# STM32H730 register map
File version: 1.9
CPU: CM7 r0p1, little endian, MPU, FPU, 4 interrupt priority bits
Registers are 32-bit, read-write, reset 0x0 unless marked. A register's access mark holds for its fields unless they carry their own. Offsets are from the block's base; [hi:lo] are bit positions; {n}, {i} and the like mark numbered series.

## CRC — Cryptographic processor
Base 0x58024C00
0x00 DR reset 0xFFFFFFFF — Data register
  [31:0] DR — Data Register
0x04 IDR — Independent Data register
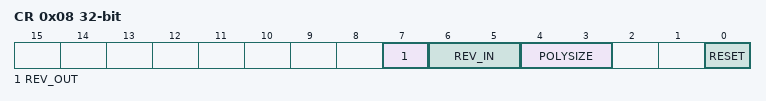
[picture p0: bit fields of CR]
0x08 CR access per field — Control register
  [7] REV_OUT rw — Reverse output data
  [6:5] REV_IN rw — Reverse input data
  [4:3] POLYSIZE rw — Polynomial size
  [0] RESET wo — RESET bit
0x10 INIT — Initial CRC value
  [31:0] CRC_INIT — Programmable initial CRC value
0x14 POL reset 0x4C11DB7 — CRC polynomial
  [31:0] POL — Programmable polynomial

## CRYP — Cryptographic processor
Base 0x48021000
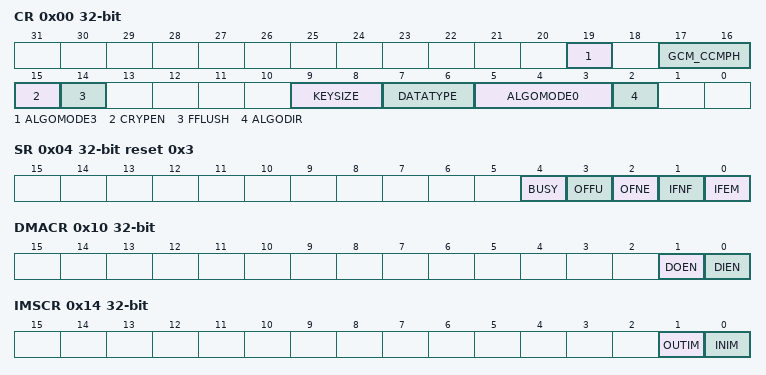
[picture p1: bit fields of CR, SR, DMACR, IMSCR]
0x00 CR access per field — control register
  [19] ALGOMODE3 rw — ALGOMODE
  [17:16] GCM_CCMPH rw
  [15] CRYPEN rw — Cryptographic processor enable
  [14] FFLUSH wo — FIFO flush
  [9:8] KEYSIZE rw — Key size selection (AES mode only)
  [7:6] DATATYPE rw — Data type selection
  [5:3] ALGOMODE0 rw — Algorithm mode
  [2] ALGODIR rw — Algorithm direction
0x04 SR ro reset 0x3 — status register
  [4] BUSY — Busy bit
  [3] OFFU — Output FIFO full
  [2] OFNE — Output FIFO not empty
  [1] IFNF — Input FIFO not full
  [0] IFEM — Input FIFO empty
0x08 DIN — data input register
  [31:0] DATAIN — Data input
0x0C DOUT ro — data output register
  [31:0] DATAOUT — Data output
0x10 DMACR — DMA control register
  [1] DOEN — DMA output enable
  [0] DIEN — DMA input enable
0x14 IMSCR — interrupt mask set/clear register
  [1] OUTIM — Output FIFO service interrupt mask
  [0] INIM — Input FIFO service interrupt mask
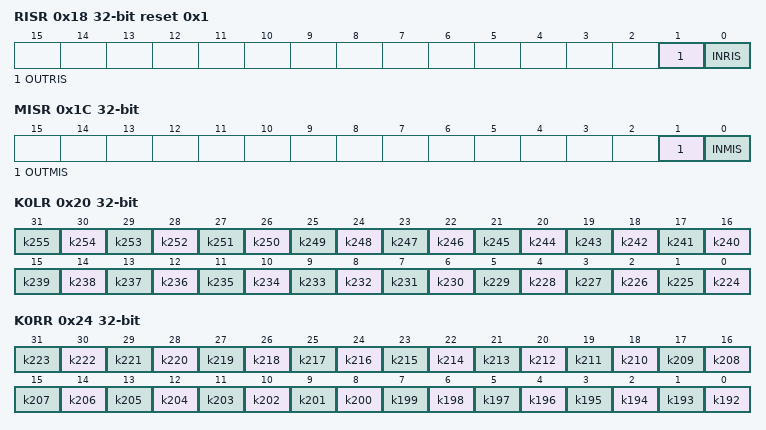
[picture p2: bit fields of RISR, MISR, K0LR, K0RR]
0x18 RISR ro reset 0x1 — raw interrupt status register
  [1] OUTRIS — Output FIFO service raw interrupt status
  [0] INRIS — Input FIFO service raw interrupt status
0x1C MISR ro — masked interrupt status register
  [1] OUTMIS — Output FIFO service masked interrupt status
  [0] INMIS — Input FIFO service masked interrupt status
0x20 K0LR wo — key registers
  [n-224] k{n} (n=224..255)
0x24 K0RR wo — key registers
  [n-192] k{n} (n=192..223)
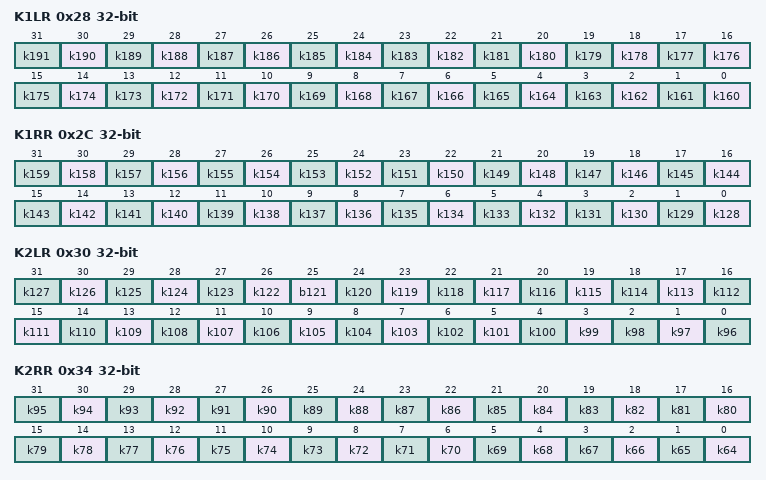
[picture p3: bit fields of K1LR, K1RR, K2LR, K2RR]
0x28 K1LR wo — key registers
  [n-160] k{n} (n=160..191)
0x2C K1RR wo — key registers
  [n-128] k{n} (n=128..159)
0x30 K2LR wo — key registers
  [n-96] k{n} (n=122..127), [25] b121, [n-96] k{n} (n=96..120)
0x34 K2RR wo — key registers
  [n-64] k{n} (n=64..95)
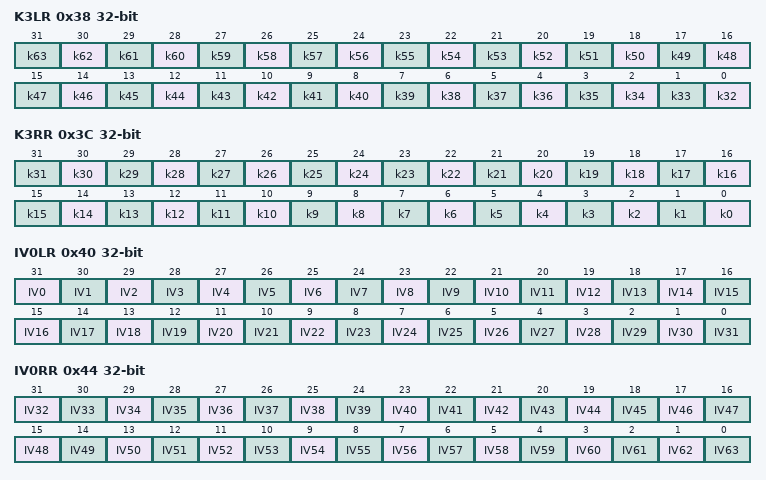
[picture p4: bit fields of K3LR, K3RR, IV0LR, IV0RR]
0x38 K3LR wo — key registers
  [n-32] k{n} (n=32..63)
0x3C K3RR wo — key registers
  [n] k{n} (n=0..31)
0x40 IV0LR — Initialization vector register 0L
  [31-n] IV{n} (n=0..31)
0x44 IV0RR — initialization vector register 0R
  [63-n] IV{n} (n=32..63)
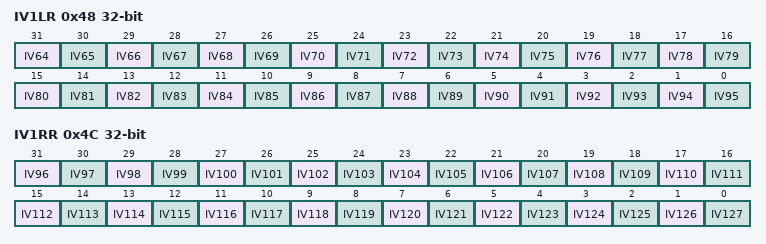
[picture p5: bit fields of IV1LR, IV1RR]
0x48 IV1LR — Initialization vector register 1L
  [95-n] IV{n} (n=64..95)
0x4C IV1RR — Initialization vector register 1R
  [127-n] IV{n} (n=96..127)
{0x50+4i} CSGCMCCM{i}R (i=0..7) — context swap register
{0x70+4i} CSGCM{i}R (i=0..7) — context swap register

## DCMI — Digital camera interface
Base 0x48020000
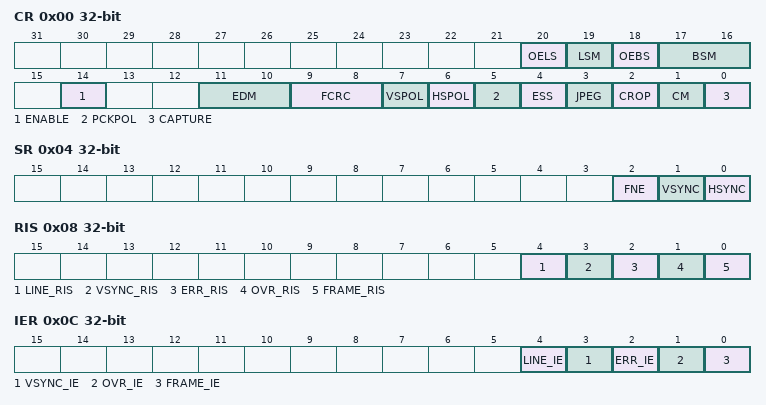
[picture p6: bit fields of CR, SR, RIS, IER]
0x00 CR — control register 1
  [20] OELS — Odd/Even Line Select (Line Select Start)
  [19] LSM — Line Select mode
  [18] OEBS — Odd/Even Byte Select (Byte Select Start)
  [17:16] BSM — Byte Select mode
  [14] ENABLE — DCMI enable
  [11:10] EDM — Extended data mode
  [9:8] FCRC — Frame capture rate control
  [7] VSPOL — Vertical synchronization polarity
  [6] HSPOL — Horizontal synchronization polarity
  [5] PCKPOL — Pixel clock polarity
  [4] ESS — Embedded synchronization select
  [3] JPEG — JPEG format
  [2] CROP — Crop feature
  [1] CM — Capture mode
  [0] CAPTURE — Capture enable
0x04 SR ro — status register
  [2] FNE — FIFO not empty
  [1] VSYNC
  [0] HSYNC
0x08 RIS ro — raw interrupt status register
  [4] LINE_RIS — Line raw interrupt status
  [3] VSYNC_RIS — VSYNC raw interrupt status
  [2] ERR_RIS — Synchronization error raw interrupt status
  [1] OVR_RIS — Overrun raw interrupt status
  [0] FRAME_RIS — Capture complete raw interrupt status
0x0C IER — interrupt enable register
  [4] LINE_IE — Line interrupt enable
  [3] VSYNC_IE — VSYNC interrupt enable
  [2] ERR_IE — Synchronization error interrupt enable
  [1] OVR_IE — Overrun interrupt enable
  [0] FRAME_IE — Capture complete interrupt enable
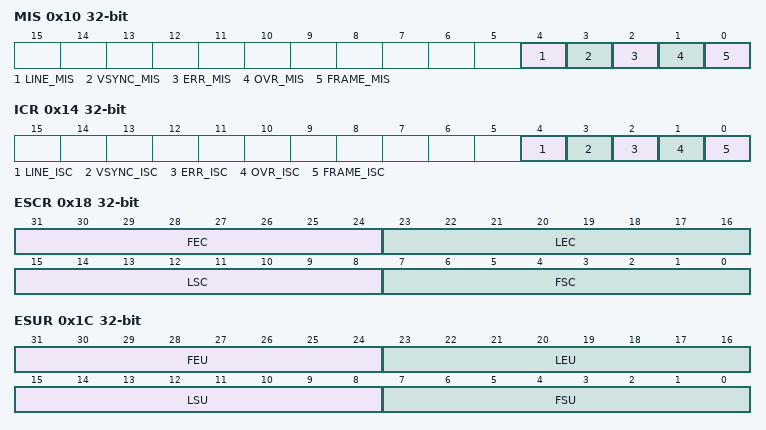
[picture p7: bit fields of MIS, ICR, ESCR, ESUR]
0x10 MIS ro — masked interrupt status register
  [4] LINE_MIS — Line masked interrupt status
  [3] VSYNC_MIS — VSYNC masked interrupt status
  [2] ERR_MIS — Synchronization error masked interrupt status
  [1] OVR_MIS — Overrun masked interrupt status
  [0] FRAME_MIS — Capture complete masked interrupt status
0x14 ICR wo — interrupt clear register
  [4] LINE_ISC — line interrupt status clear
  [3] VSYNC_ISC — Vertical synch interrupt status clear
  [2] ERR_ISC — Synchronization error interrupt status clear
  [1] OVR_ISC — Overrun interrupt status clear
  [0] FRAME_ISC — Capture complete interrupt status clear
0x18 ESCR — embedded synchronization code register
  [31:24] FEC — Frame end delimiter code
  [23:16] LEC — Line end delimiter code
  [15:8] LSC — Line start delimiter code
  [7:0] FSC — Frame start delimiter code
0x1C ESUR — embedded synchronization unmask register
  [31:24] FEU — Frame end delimiter unmask
  [23:16] LEU — Line end delimiter unmask
  [15:8] LSU — Line start delimiter unmask
  [7:0] FSU — Frame start delimiter unmask
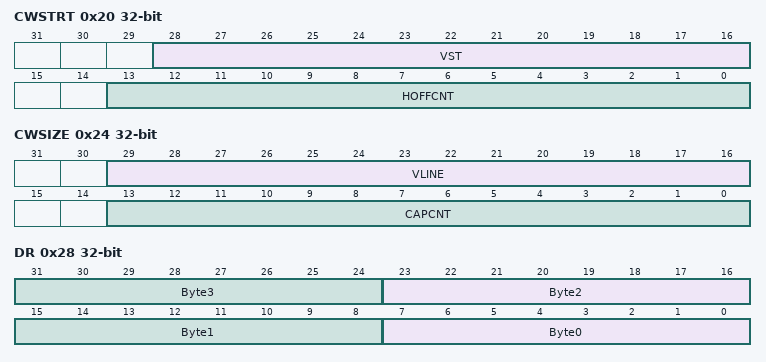
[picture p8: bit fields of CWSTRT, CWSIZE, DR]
0x20 CWSTRT — crop window start
  [28:16] VST — Vertical start line count
  [13:0] HOFFCNT — Horizontal offset count
0x24 CWSIZE — crop window size
  [29:16] VLINE — Vertical line count
  [13:0] CAPCNT — Capture count
0x28 DR ro — data register
  [8n+7:8n] Byte{n} (n=0..3) — Data byte {n}
